# STM32G473xx register map
File version: 1.0
Registers are 32-bit, read-write, reset 0x0 unless marked. A register's access mark holds for its fields unless they carry their own. Offsets are from the block's base; [hi:lo] are bit positions; {n}, {i} and the like mark numbered series.

## SYSCFG — System configuration controller
Base 0x40010000
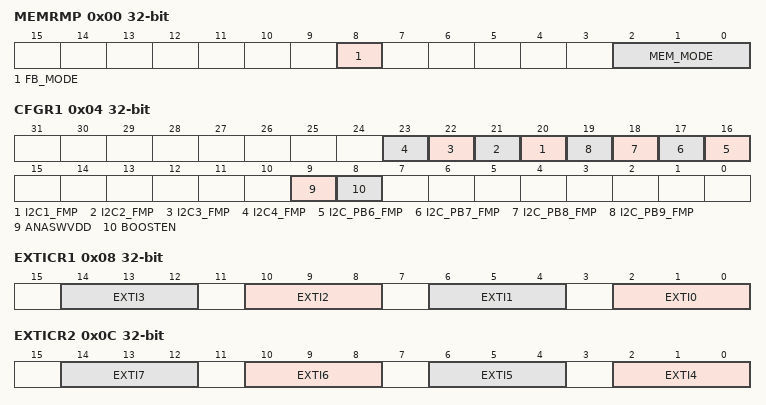
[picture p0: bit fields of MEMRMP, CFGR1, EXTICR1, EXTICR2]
0x00 MEMRMP — SYSCFG memory remap register
  [8] FB_MODE — User Flash Bank mode selection
    0=BANK1; 1=BANK2
  [2:0] MEM_MODE — SYSCFG_Memory Remap Config
    0=FLASH (Main Flash memory mapped at 0x00000000); 1=SYSTEMFLASH (System Flash memory mapped at 0x00000000); 3=SRAM (SRAM1 mapped at 0x00000000); 2=FMC (FMC bank 1 (NOR/PSRAM 1 and 2) mapped at 0x00000000); 6=QUADSPI (QUADSPI memory mapped at 0x00000000)
0x04 CFGR1 — SYSCFG configuration register 1
  [n+19] I2C{n}_FMP (n=1..4) — I2C{n} Fast mode plus
  [n+10] I2C_PB{n}_FMP (n=6..9) — I2C PB{n} Fast mode plus
  [9] ANASWVDD — GPIO analog switch control voltage selection
  [8] BOOSTEN — I/O analog switch voltage booster enable
0x08 EXTICR1 — SYSCFG external interrupt configuration registers
  [4n+2:4n] EXTI{n} (n=0..3) — EXTI {n} configuration
0x0C EXTICR2 — SYSCFG external interrupt configuration registers
  [4n-14:4n-16] EXTI{n} (n=4..7) — EXTI {n} configuration
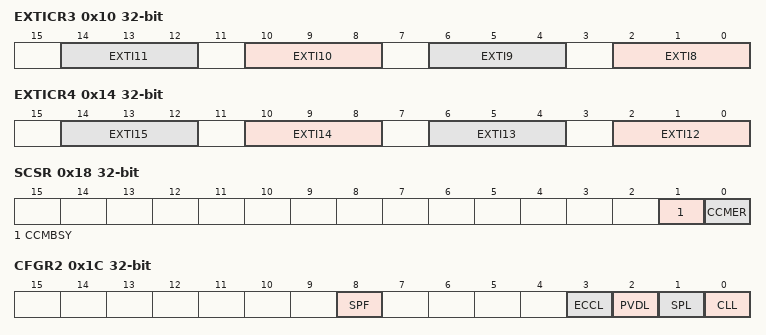
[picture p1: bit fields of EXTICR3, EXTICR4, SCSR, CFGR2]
0x10 EXTICR3 — SYSCFG external interrupt configuration registers
  [4n-30:4n-32] EXTI{n} (n=8..11) — EXTI {n} configuration
0x14 EXTICR4 — SYSCFG external interrupt configuration registers
  [4n-46:4n-48] EXTI{n} (n=12..15) — EXTI {n} configuration
0x18 SCSR — SYSCFG CCMSRAM control and status register
  [1] CCMBSY — CCMSRAM Erase Ongoing
  [0] CCMER — CCMSRAM Erase Request
0x1C CFGR2 — SYSCFG configuration register 2
  [8] SPF — SRAM Parity Flag
  [3] ECCL — ECC Lock
  [2] PVDL — PVD Lock
  [1] SPL — SRAM Parity Lock
  [0] CLL — Core Lockup Lock
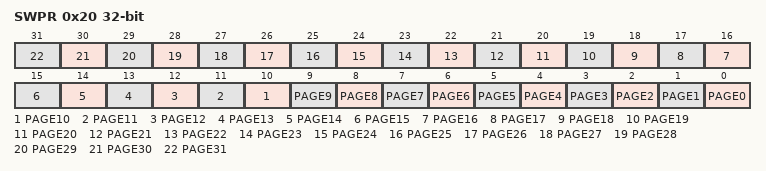
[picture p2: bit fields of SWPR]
0x20 SWPR — SYSCFG CCMSRAM write protection register
  [n] PAGE{n} (n=0..31) — CCMSRAM Write protection page {n}
0x24 SKR — SYSCFG CCMSRAM Key Register
  [7:0] KEY — CCMSRAM write protection key for software erase

## VREFBUF
Base 0x40010030
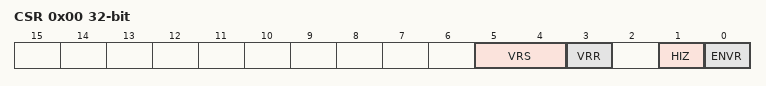
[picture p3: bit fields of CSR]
0x00 CSR — VREFBUF control and status register
  [5:4] VRS — VRS[5:0] bits (Voltage reference scale)
    0=SCALE0 (Voltage reference scale 0 (VREFBUF_OUT = 2.048V)); 1=SCALE1 (Voltage reference scale 1 (VREFBUF_OUT = 2.5V)); 2=SCALE2 (Voltage reference scale 2 (VREFBUF_OUT = 2.9V))
  [3] VRR — Voltage reference buffer ready
  [1] HIZ — High impedance mode
  [0] ENVR — Voltage reference buffer enable
0x04 CCR — VREFBUF calibration and control register
  [5:0] TRIM — TRIM[5:0] bits (Trimming code)

## COMP1 — Comparator
Base 0x40010200
Same registers: COMP2 0x40010204, COMP3 0x40010208, COMP4 0x4001020C, COMP5 0x40010210, COMP6 0x40010214, COMP7 0x40010218
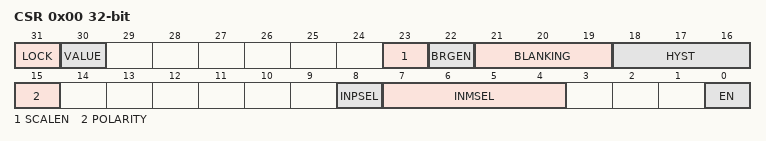
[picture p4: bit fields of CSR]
0x00 CSR — COMP control and status register
  [31] LOCK — Comparator lock
  [30] VALUE — Comparator output level
  [23] SCALEN — Comparator voltage scaler enable
  [22] BRGEN — Comparator scaler bridge enable
  [21:19] BLANKING — Comparator blanking source
    0=NONE (Comparator output without blanking); 1=TIM1_OC5_COMP1 (Comparator output blanking source TIM1 OC5 (specific to COMP instance: COMP1). Note: For COMPx instance availability, please refer to datasheet); 4=TIM1_OC5_COMP4 (Comparator output blanking source TIM1 OC5 (specific to COMP instance: COMP4). Note: For COMPx instance availability, please refer to datasheet); 2=TIM2_OC3_COMP1 (Comparator output blanking source TIM2 OC3 (specific to COMP instance: COMP1). Note: For COMPx instance availability, please refer to datasheet); 3=TIM2_OC4_COMP3 (Comparator output blanking source TIM2 OC4 (specific to COMP instance: COMP3). Note: For COMPx instance availability, please refer to datasheet); 5=TIM20_OC5 (Comparator output blanking source TIM20 OC5 (Common to all COMP instances). Note: For TIM20 instance availability, please refer to datasheet); 6=TIM15_OC1 (Comparator output blanking source TIM15 OC1 (Common to all COMP instances).); 7=TIM4_OC3 (Comparator output blanking source TIM4 OC3 (Common to all COMP instances).)
  [18:16] HYST — Comparator hysteresis
    0=NONE (No hysteresis); 1=HYSTERESIS_10MV (Hysteresis level 10mV); 2=HYSTERESIS_20MV (Hysteresis level 20mV); 3=HYSTERESIS_30MV (Hysteresis level 30mV); 4=HYSTERESIS_40MV (Hysteresis level 40mV); 5=HYSTERESIS_50MV (Hysteresis level 50mV); 6=HYSTERESIS_60MV (Hysteresis level 60mV); 7=HYSTERESIS_70MV (Hysteresis level 70mV)
  [15] POLARITY — Comparator output polarity
    0=NONINVERTED (COMP output polarity is not inverted: comparator output is high when the plus (non-inverting) input is at a higher voltage than the minus (inverting) input); 1=INVERTED (COMP output polarity is inverted: comparator output is low when the plus (non-inverting) input is at a lower voltage than the minus (inverting) input)
  [8] INPSEL — Comparator input plus selection
    0=IO1 (Comparator input plus connected to IO1 (pin PA1 for COMP1, pin PA7 for COMP2, pin PA0 for COMP3, pin PB0 for COMP4, pin PB13 for COMP5, pin PB11 for COMP6, pin PB14 for COMP7). Note: For COMPx instance availability, please refer to datasheet); 1=IO2 (Comparator input plus connected to IO2 (pin PB1 for COMP1, pin PA3 for COMP2, pin PC1 for COMP3, pin PE7 for COMP4, pin PD12 for COMP5, pin PD11 for COMP6, pin PD14 for COMP7). Note: For COMPx instance availability, please refer to datasheet)
  [7:4] INMSEL — Comparator input minus selection
  [0] EN — Comparator enable
